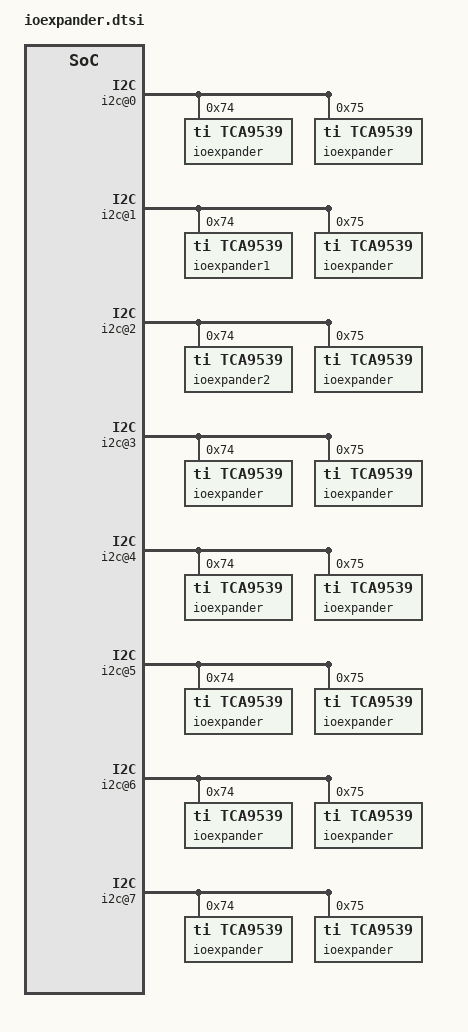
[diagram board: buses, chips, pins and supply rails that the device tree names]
/* IO Expander bits */
  i2c@0 {
    #address-cells = <1>;
    #size-cells = <0>;
    reg = <0>;

      ioexpander@74 {
       compatible = "ti,tca9539";
      reg = <0x74>;
      };

      ioexpander@75 {
       compatible = "ti,tca9539";
       reg = <0x75>;
      };

    };

  i2c@1 {
    #address-cells = <1>;
    #size-cells = <0>;
    reg = <1>;

      ioexpander1@74 {
       compatible = "ti,tca9539";
      reg = <0x74>;
      };

      ioexpander@75 {
       compatible = "ti,tca9539";
       reg = <0x75>;
      };

    };

    i2c@2 {
    #address-cells = <1>;
    #size-cells = <0>;
    reg = <2>;

      ioexpander2@74 {
       compatible = "ti,tca9539";
      reg = <0x74>;
      };

      ioexpander@75 {
       compatible = "ti,tca9539";
       reg = <0x75>;
      };

    };

    i2c@3 {
    #address-cells = <1>;
    #size-cells = <0>;
    reg = <3>;

      ioexpander@74 {
       compatible = "ti,tca9539";
      reg = <0x74>;
      };

      ioexpander@75 {
       compatible = "ti,tca9539";
       reg = <0x75>;
      };

    };

    i2c@4 {
    #address-cells = <1>;
    #size-cells = <0>;
    reg = <4>;

      ioexpander@74 {
       compatible = "ti,tca9539";
      reg = <0x74>;
      };

      ioexpander@75 {
       compatible = "ti,tca9539";
       reg = <0x75>;
      };

    };

    i2c@5 {
    #address-cells = <1>;
    #size-cells = <0>;
    reg = <5>;

      ioexpander@74 {
       compatible = "ti,tca9539";
      reg = <0x74>;
      };

      ioexpander@75 {
       compatible = "ti,tca9539";
       reg = <0x75>;
      };

    };

    i2c@6 {
    #address-cells = <1>;
    #size-cells = <0>;
    reg = <6>;

      ioexpander@74 {
       compatible = "ti,tca9539";
      reg = <0x74>;
      };

      ioexpander@75 {
       compatible = "ti,tca9539";
       reg = <0x75>;
      };

    };

    i2c@7 {
    #address-cells = <1>;
    #size-cells = <0>;
    reg = <7>;

      ioexpander@74 {
       compatible = "ti,tca9539";
      reg = <0x74>;
      };

      ioexpander@75 {
       compatible = "ti,tca9539";
       reg = <0x75>;
      };

    };
